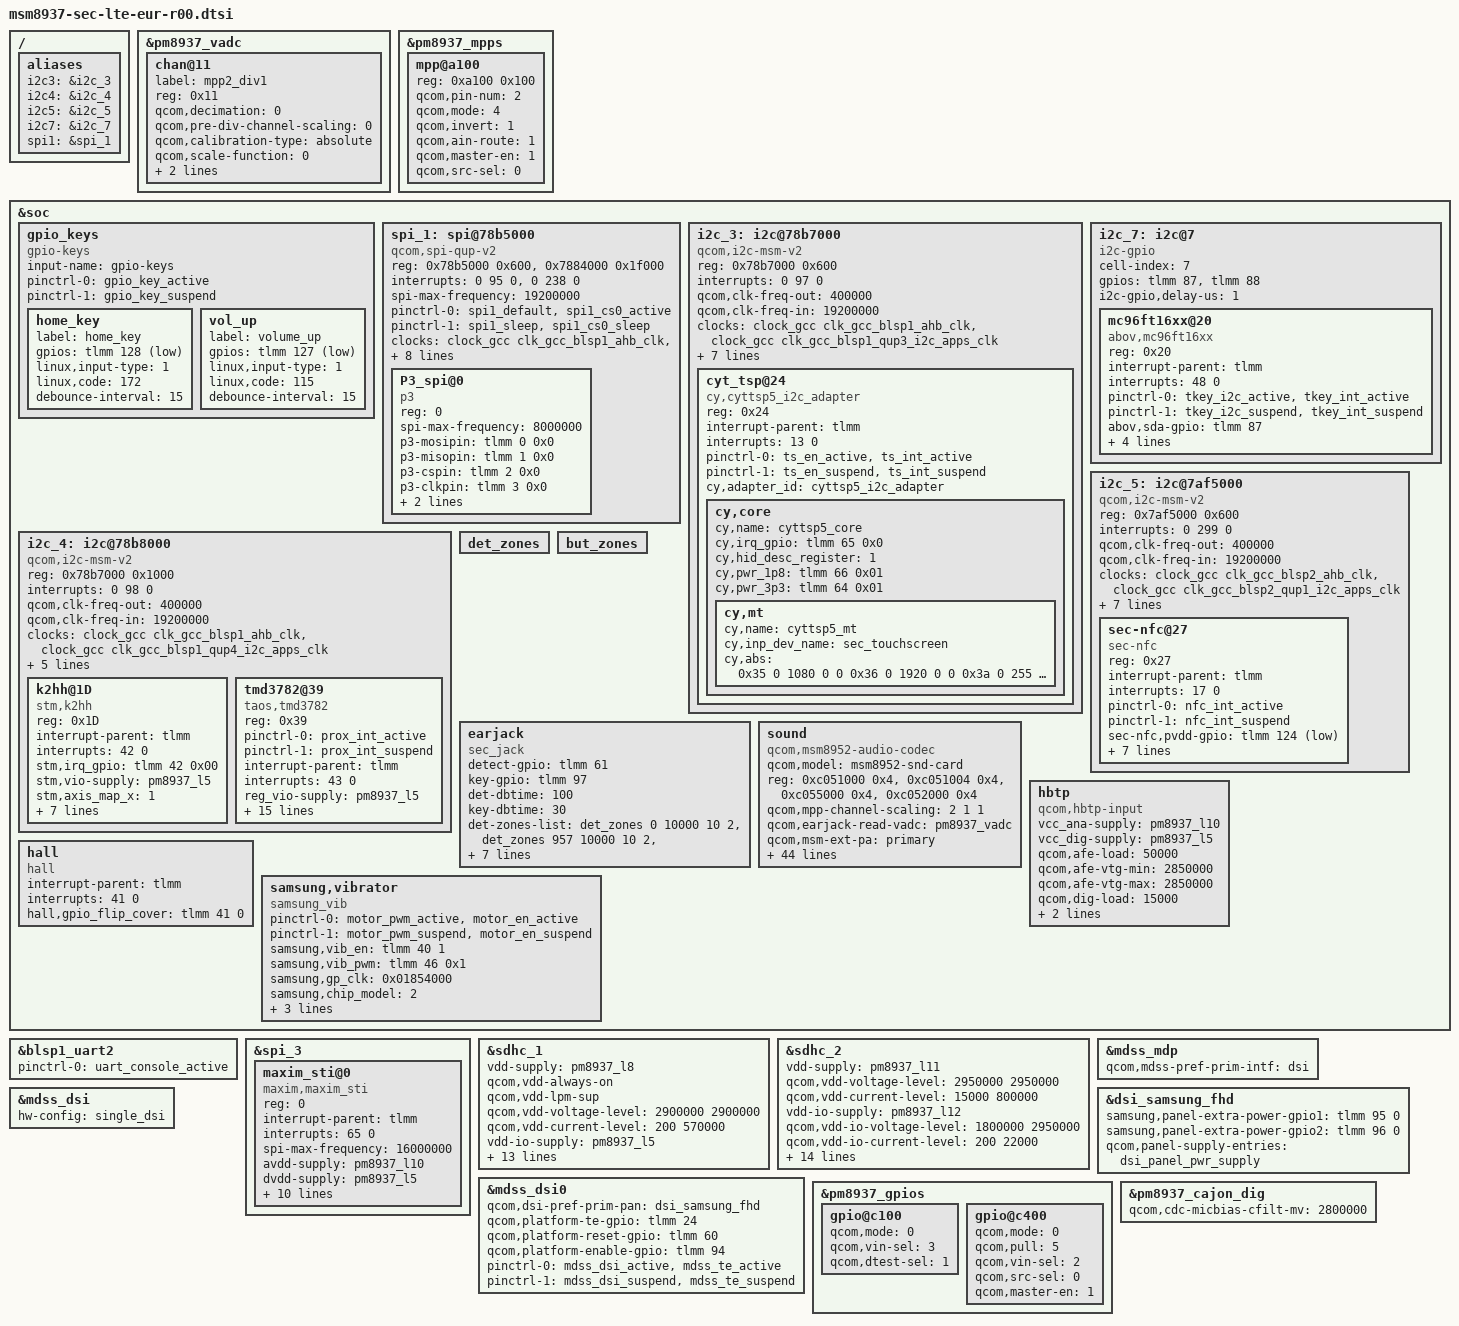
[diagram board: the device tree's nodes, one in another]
/*
 * Copyright (c) 2015, The Linux Foundation. All rights reserved.
 *
 * This program is free software; you can redistribute it and/or modify
 * it under the terms of the GNU General Public License version 2 and
 * only version 2 as published by the Free Software Foundation.
 *
 * This program is distributed in the hope that it will be useful,
 * but WITHOUT ANY WARRANTY; without even the implied warranty of
 * MERCHANTABILITY or FITNESS FOR A PARTICULAR PURPOSE.  See the
 * GNU General Public License for more details.
 */

#include "msm8937-sec-lte-common.dtsi"
#include "msm8937-pinctrl-sec-lte-eur-r00.dtsi"
#include "msm8937-camera-sensor-cdp.dtsi"

#include "msm8937-s2mu005.dtsi"
#include "msm8937-sec-lte-eur-battery-r00.dtsi"
#include <dt-bindings/clock/msm-clocks-8952.h>

/*
&flash_led {
	compatible = "qcom,qpnp-flash-led";
	reg = <0xd300 0x100>;
	pinctrl-names = "flash_led_enable","flash_led_disable";
	pinctrl-0 = <&rear_flash_led_enable>;
	pinctrl-1 = <&rear_flash_led_disable>;
	qcom,follow-otst2-rb-disabled;
};
*/
/{
	aliases {
		i2c3 = &i2c_3;
		i2c4 = &i2c_4;
		i2c5 = &i2c_5;
		i2c7 = &i2c_7;
		spi1 = &spi_1;
	};
};

&pm8937_vadc {
	chan@11 {
		label = "mpp2_div1";
		reg = <0x11>;
		qcom,decimation = <0>;
		qcom,pre-div-channel-scaling = <0>;
		qcom,calibration-type = "absolute";
		qcom,scale-function = <0>;
		qcom,hw-settle-time = <5>;
		qcom,fast-avg-setup = <0>;
	};
};

&pm8937_mpps {
	mpp@a100 {
		reg = <0xa100 0x100>;
		qcom,pin-num = <2>;
		qcom,mode = <4>; /* AIN input */
		qcom,invert = <1>; /* Enable MPP */
		qcom,ain-route = <1>; /* AMUX 6 */
		qcom,master-en = <1>;
		qcom,src-sel = <0>; /* Function constant */
		status = "okay";
	};
};
	
&soc {
	gpio_keys {
		compatible = "gpio-keys";
		input-name = "gpio-keys";
		pinctrl-names = "tlmm_gpio_key_active","tlmm_gpio_key_suspend";
		pinctrl-0 = <&gpio_key_active>;
		pinctrl-1 = <&gpio_key_suspend>;

		home_key {
			label = "home_key";
			gpios = <&tlmm 128 0x1>;
			linux,input-type = <1>;
			linux,code = <172>;
			debounce-interval = <15>;
		};

		vol_up {
			label = "volume_up";
			gpios = <&tlmm 127 0x1>;
			linux,input-type = <1>;
			linux,code = <115>;
			debounce-interval = <15>;
		};
	};
	
	/delete-node/ spi@0x78B5000;
	
	spi_1: spi@78b5000 { /* BLSP1 QUP0 */
		status = "ok";
		compatible = "qcom,spi-qup-v2";
		#address-cells = <1>;
		#size-cells = <0>;
		reg-names = "spi_physical", "spi_bam_physical";
		reg = <0x78b5000 0x600>,
			<0x7884000 0x1f000>;
		interrupt-names = "spi_irq", "spi_bam_irq";
		interrupts = <0 95 0>, <0 238 0>;
		spi-max-frequency = <19200000>;
		pinctrl-names = "spi_default", "spi_sleep";
		pinctrl-0 = <&spi1_default &spi1_cs0_active>;
		pinctrl-1 = <&spi1_sleep &spi1_cs0_sleep>;
		clocks = <&clock_gcc clk_gcc_blsp1_ahb_clk>,
			<&clock_gcc clk_gcc_blsp1_qup1_spi_apps_clk>;
		clock-names = "iface_clk", "core_clk";
		qcom,infinite-mode = <0>;
		qcom,use-bam;
		qcom,use-pinctrl;
		qcom,ver-reg-exists;
		qcom,bam-consumer-pipe-index = <4>;
		qcom,bam-producer-pipe-index = <5>;
		qcom,master-id = <86>;
		
		P3_spi@0 {
			compatible = "p3";
			reg = <0>;
			spi-max-frequency = <8000000>;
			p3-mosipin = <&tlmm 0 0x0>;
			p3-misopin = <&tlmm 1 0x0>;
			p3-cspin = <&tlmm 2 0x0>;
			p3-clkpin = <&tlmm 3 0x0>;
			p3-ese_pwr_req = <&tlmm 129 0>;
			p3-test = <0xBB>;
		};

	};

	i2c_3: i2c@78b7000 { /* BLSP1 QUP3 */
		compatible = "qcom,i2c-msm-v2";
		#address-cells = <1>;
		#size-cells = <0>;
		reg-names = "qup_phys_addr";
		reg = <0x78b7000 0x600>;
		interrupt-names = "qup_irq";
		interrupts = <0 97 0>;
		qcom,clk-freq-out = <400000>;
		qcom,clk-freq-in  = <19200000>;
		clock-names = "iface_clk", "core_clk";
		clocks = <&clock_gcc clk_gcc_blsp1_ahb_clk>,
			<&clock_gcc clk_gcc_blsp1_qup3_i2c_apps_clk>;

		pinctrl-names = "i2c_active", "i2c_sleep";
		pinctrl-0 = <&i2c_3_active>;
		pinctrl-1 = <&i2c_3_sleep>;
		qcom,noise-rjct-scl = <0>;
		qcom,noise-rjct-sda = <0>;
		qcom,master-id = <86>;
		dmas = <&dma_blsp1 8 64 0x20000020 0x20>,
			<&dma_blsp1 9 32 0x20000020 0x20>;
		dma-names = "tx", "rx";
		/*status = "disabled";*/
	
	};

	i2c@78b7000 { /* BLSP1 QUP2 */
                cyt_tsp@24 {
                        compatible = "cy,cyttsp5_i2c_adapter";
                        reg = <0x24>; /*slave address*/
                        interrupt-parent = <&tlmm>;
                        interrupts = <13 0>; /* Touch int gpio */
                        pinctrl-names = "tsp_i2c_gpio_active", "tsp_i2c_suspend";
                        pinctrl-0 = <&ts_en_active &ts_int_active>;
                        pinctrl-1 = <&ts_en_suspend &ts_int_suspend>;
                        cy,adapter_id = "cyttsp5_i2c_adapter";

				cy,core {
					cy,name = "cyttsp5_core";
					cy,irq_gpio = <&tlmm 65 0x0>;
					cy,hid_desc_register = <1>;
					cy,pwr_1p8 = <&tlmm 66 0x01>;
					cy,pwr_3p3 = <&tlmm 64 0x01>;  /* Touch En2 gpio */
					/*cy,ta_gpio = <&tlmm 98 0x01>; */
					cy,mt {
						cy,name = "cyttsp5_mt";
						cy,inp_dev_name = "sec_touchscreen";
						cy,abs =
							/* ABS_MT_POSITION_X, CY_ABS_MIN_X, CY_ABS_MAX_X, 0, 0 */
							<0x35 0 1080 0 0
							/* ABS_MT_POSITION_Y, CY_ABS_MIN_Y, CY_ABS_MAX_Y, 0, 0 */
							0x36 0 1920 0 0
							/* ABS_MT_PRESSURE, CY_ABS_MIN_P, CY_ABS_MAX_P, 0, 0 */
							0x3a 0 255 0 0
							/* CY_IGNORE_VALUE, CY_ABS_MIN_W, CY_ABS_MAX_W, 0, 0 */
							0xffff 0 255 0 0
							/* ABS_MT_TRACKING_ID, CY_ABS_MIN_T, CY_ABS_MAX_T, 0, 0 */
							0x39 0 15 0 0
							/* ABS_MT_TOUCH_MAJOR, 0, 255, 0, 0 */
							0x30 0 255 0 0
							/* ABS_MT_TOUCH_MINOR, 0, 255, 0, 0 */
							0x31 0 255 0 0
							/* ABS_MT_ORIENTATION, -128, 127, 0, 0 */
							0x34 0xfffffed7 127 0 0
							/* ABS_MT_TOOL_TYPE, 0, MT_TOOL_MAX, 0, 0 */
							0x37 0 1 0 0>;
					};
				};
                };
	};

	i2c_7: i2c@7 {
		cell-index = <7>;
		compatible = "i2c-gpio";
		gpios = <&tlmm 87 0 /* sda */
			&tlmm 88 0 /* scl */
			>;
		i2c-gpio,delay-us = <1>;
		#address-cells = <1>;
		#size-cells = <0>;
		mc96ft16xx@20{
			compatible = "abov,mc96ft16xx";
			reg = <0x20>;
			interrupt-parent = <&tlmm>;
			interrupts = <48 0>;
			pinctrl-names = "touchkey_active", "touchkey_suspend";
			pinctrl-0 = <&tkey_i2c_active &tkey_int_active>;
			pinctrl-1 = <&tkey_i2c_suspend &tkey_int_suspend>;
			abov,sda-gpio = <&tlmm 87 0>;
			abov,scl-gpio = <&tlmm 88 0>;
			abov,irq-gpio = <&tlmm 48 0>;
			abov,tkey_en-gpio = <&tlmm 92 0>;
			/*abov,tkey_led_en-gpio = <&tlmm 91 0>;*/
			vddo-supply = <&pm8937_l6>;
		};
	};

	i2c_4: i2c@78b8000 { /* BLSP1 QUP4 */
		compatible = "qcom,i2c-msm-v2";
		#address-cells = <1>;
		#size-cells = <0>;
		reg-names = "qup_phys_addr";
		reg = <0x78b7000 0x1000>;
		interrupt-names = "qup_irq";
		interrupts = <0 98 0>;
		qcom,clk-freq-out = <400000>;
		qcom,clk-freq-in  = <19200000>;
		clock-names = "iface_clk", "core_clk";
		clocks = <&clock_gcc clk_gcc_blsp1_ahb_clk>,
			<&clock_gcc clk_gcc_blsp1_qup4_i2c_apps_clk>;

		pinctrl-names = "i2c_active", "i2c_sleep";
		pinctrl-0 = <&i2c_4_active>;
		pinctrl-1 = <&i2c_4_sleep>;
		qcom,noise-rjct-scl = <0>;
		qcom,noise-rjct-sda = <0>;
		qcom,master-id = <86>;
		//dmas = <&dma_blsp1 8 64 0x20000020 0x20>,
		//	<&dma_blsp1 9 32 0x20000020 0x20>;
		//dma-names = "tx", "rx";
		/*status = "disabled";*/
	};
	i2c_4: i2c@78b8000 { /* BLSP1 QUP4 */
		k2hh@1D {
			compatible = "stm,k2hh";
			reg = <0x1D>;
			interrupt-parent = <&tlmm>;
			interrupts = <42 0>;
			stm,irq_gpio = <&tlmm 42 0x00>;
			stm,vio-supply = <&pm8937_l5>;
			stm,axis_map_x = <1>;
			stm,axis_map_y = <0>;
			stm,axis_map_z = <2>;
			stm,negate_x = <0>;
			stm,negate_y = <1>;
			stm,negate_z = <1>;
			stm,poll_interval = <100>;
			stm,min_interval = <2>;
		};
		tmd3782@39 {
			compatible = "taos,tmd3782";
			reg = <0x39>;
			pinctrl-names = "default";
			pinctrl-0 = <&prox_int_active>;
			pinctrl-1 = <&prox_int_suspend>;
			interrupt-parent = <&tlmm>;
			interrupts = <43 0>;
			reg_vio-supply = <&pm8937_l5>;
			reg_vdd-supply = <&pm8937_l17>;
			taos,irq_gpio = <&tlmm 43 0x1>;
			taos,prox_rawdata_trim = <170>;
			taos,prox_thresh_hi = <480>;
			taos,prox_thresh_low = <340>;
			taos,als_time = <0xEB>;
			taos,intr_filter = <0x33>;
			taos,prox_pulsecnt = <0x06>;
			taos,als_gain = <0x22>;
			taos,coef_atime = <50>;
			taos,ga = <97>;
			taos,coef_a = <1000>;
			taos,coef_b = <1880>;
			taos,coef_c = <642>;
			taos,coef_d = <1140>;
		};
	};

	i2c_5: i2c@7af5000 { /* BLSP2 QUP1 */
		compatible = "qcom,i2c-msm-v2";
		#address-cells = <1>;
		#size-cells = <0>;
		reg-names = "qup_phys_addr";
		reg = <0x7af5000 0x600>;
		interrupt-names = "qup_irq";
		interrupts = <0 299 0>;
		qcom,clk-freq-out = <400000>;
		qcom,clk-freq-in  = <19200000>;
		clock-names = "iface_clk", "core_clk";
		clocks = <&clock_gcc clk_gcc_blsp2_ahb_clk>,
			<&clock_gcc clk_gcc_blsp2_qup1_i2c_apps_clk>;

		pinctrl-names = "i2c_active", "i2c_sleep";
		pinctrl-0 = <&i2c_5_active>;
		pinctrl-1 = <&i2c_5_sleep>;
		qcom,noise-rjct-scl = <0>;
		qcom,noise-rjct-sda = <0>;
		qcom,master-id = <84>;
		dmas = <&dma_blsp2 4 64 0x20000020 0x20>,
			<&dma_blsp2 5 32 0x20000020 0x20>;
		dma-names = "tx", "rx";
	};
	i2c_5: i2c@7af5000 { 				
		sec-nfc@27 {
			compatible = "sec-nfc";
			reg = <0x27>;
			interrupt-parent = <&tlmm>;
			interrupts = <17 0>;
			pinctrl-names = "nfc_active","nfc_suspend";
			pinctrl-0 = <&nfc_int_active>;
			pinctrl-1 = <&nfc_int_suspend>;
			sec-nfc,pvdd-gpio = <&tlmm 124 0x01>;
			sec-nfc,firm-gpio = <&tlmm 13 0>;
			sec-nfc,ven-gpio = <&tlmm 16 0>;
			sec-nfc,irq-gpio = <&tlmm 17 0x00>;
			nfc_ldo-supply = <&pm8937_l14>;
			qcom,clk-src = "BBCLK2";
			qcom,clk-gpio = <&pm8937_gpios 5 0x00>;
			clocks = <&clock_gcc clk_bb_clk2_pin>;
			clock-names = "nfc_clock";
		};			
	};

	det_zones: det_zones {
		#list-det-cells = <4>;
	};

	but_zones: but_zones {
		#list-but-cells = <3>;
	};

	earjack {
		compatible = "sec_jack";
		detect-gpio = <&tlmm 61 0x0>;
		key-gpio = <&tlmm 97 0x0>;
		det-dbtime = <100>;
		key-dbtime = <30>;

		det-zones-list = <&det_zones 0 10000 10 2>,
				 <&det_zones 957 10000 10 2>,
				 <&det_zones 1057 10000 10 1>,
				 <&det_zones 9999 10000 10 1>;
		but-zones-list = <&but_zones 226 0 290>, /* KEY_MEDIA:226 */
				 <&but_zones 582 291 335>, /* KEY_VOICECOMMAND:582 */
				 <&but_zones 115 336 453>, /* KEY_VOLUMEUP:115 */
				 <&but_zones 114 454 700>; /* KEY_VOLUMEDOWN:114 */

		pinctrl-names = "earjack_gpio_active",
				"earjack_gpio_suspend";
		pinctrl-0 = <&earjack_det_act &earjack_switch_act>;
		pinctrl-1 = <&earjack_det_sus &earjack_switch_sus>;
	};

	sound {
		status = "okay";
		compatible = "qcom,msm8952-audio-codec";
		qcom,model = "msm8952-snd-card";
		reg = <0xc051000 0x4>,
		      <0xc051004 0x4>,
		      <0xc055000 0x4>,
		      <0xc052000 0x4>;
		reg-names = "csr_gp_io_mux_mic_ctl",
			    "csr_gp_io_mux_spkr_ctl",
			    "csr_gp_io_lpaif_pri_pcm_pri_mode_muxsel",
			    "csr_gp_io_mux_quin_ctl";

	 	qcom,mpp-channel-scaling = <2 1 1>;
		qcom,earjack-read-vadc = <&pm8937_vadc>;
		qcom,msm-ext-pa = "primary";
		qcom,msm-mclk-freq = <9600000>; 
		qcom,msm-hs-micbias-type = "internal";
		/delete-property/qcom,hdmi-dba-codec-rx;
		/delete-property/qcom,msm-mbhc-hphl-swh;
		/delete-property/qcom,msm-mbhc-gnd-swh;
		/delete-property/qcom,msm-micbias1-ext-cap;
		qcom,audio-routing =
			"RX_BIAS", "MCLK",
			"SPK_RX_BIAS", "MCLK",
			"INT_LDO_H", "MCLK",
			"MIC BIAS External", "Handset Mic",
			"MIC BIAS External2", "Headset Mic",
			"MIC BIAS External", "Secondary Mic",
			"AMIC1", "MIC BIAS External",
			"AMIC2", "MIC BIAS External2",
			"AMIC3", "MIC BIAS External";

		qcom,msm-gpios =
			"pri_i2s";
		qcom,pinctrl-names =
			"all_off",
			"pri_i2s_act";
		pinctrl-names =
			"all_off",
			"pri_i2s_act";
		pinctrl-0 = <&cdc_pdm_lines_sus &cdc_pdm_lines_2_sus>;
		pinctrl-1 = <&cdc_pdm_lines_act &cdc_pdm_lines_2_act>;

		asoc-platform = <&pcm0>, <&pcm1>, <&pcm2>, <&voip>, <&voice>,
				<&loopback>, <&compress>, <&hostless>,
				<&afe>, <&lsm>, <&routing>, <&lpa>;
		asoc-platform-names = "msm-pcm-dsp.0", "msm-pcm-dsp.1",
				"msm-pcm-dsp.2", "msm-voip-dsp",
				"msm-pcm-voice", "msm-pcm-loopback",
				"msm-compress-dsp", "msm-pcm-hostless",
				"msm-pcm-afe", "msm-lsm-client",
				"msm-pcm-routing", "msm-pcm-lpa";
		asoc-cpu = <&dai_pri_auxpcm>,
				<&dai_mi2s0>, <&dai_mi2s1>,
				<&dai_mi2s2>, <&dai_mi2s3>,
				<&dai_mi2s5>, <&dai_mi2s6>,
				<&bt_sco_rx>, <&bt_sco_tx>,
				<&int_fm_rx>, <&int_fm_tx>,
				<&afe_pcm_rx>, <&afe_pcm_tx>,
				<&afe_proxy_rx>, <&afe_proxy_tx>,
				<&incall_record_rx>, <&incall_record_tx>,
				<&incall_music_rx>, <&incall_music_2_rx>;
		asoc-cpu-names = "msm-dai-q6-auxpcm.1",
				"msm-dai-q6-mi2s.0", "msm-dai-q6-mi2s.1",
				"msm-dai-q6-mi2s.2", "msm-dai-q6-mi2s.3",
				"msm-dai-q6-mi2s.5", "msm-dai-q6-mi2s.6",
				"msm-dai-q6-dev.12288", "msm-dai-q6-dev.12289",
				"msm-dai-q6-dev.12292", "msm-dai-q6-dev.12293",
				"msm-dai-q6-dev.224", "msm-dai-q6-dev.225",
				"msm-dai-q6-dev.241", "msm-dai-q6-dev.240",
				"msm-dai-q6-dev.32771", "msm-dai-q6-dev.32772",
				"msm-dai-q6-dev.32773", "msm-dai-q6-dev.32770";

		asoc-codec = <&stub_codec>, <&pm8937_cajon_dig>;
		asoc-codec-names = "msm-stub-codec.1", "cajon_codec";
	};


	hbtp {
		compatible = "qcom,hbtp-input";
		vcc_ana-supply = <&pm8937_l10>;
		vcc_dig-supply = <&pm8937_l5>;
		qcom,afe-load = <50000>;
		qcom,afe-vtg-min = <2850000>;
		qcom,afe-vtg-max = <2850000>;
		qcom,dig-load = <15000>;
		qcom,dig-vtg-min = <1800000>;
		qcom,dig-vtg-max = <1800000>;
	};
	
	hall {
		status = "okay";
		compatible = "hall";
		interrupt-parent = <&tlmm>;
		interrupts = <41 0>;
		hall,gpio_flip_cover = <&tlmm 41 0>;
	};
	
	samsung,vibrator {
		compatible = "samsung_vib";
		pinctrl-names = "tlmm_motor_active","tlmm_motor_suspend";
		pinctrl-0 = <&motor_pwm_active &motor_en_active>;
		pinctrl-1 = <&motor_pwm_suspend &motor_en_suspend>;
		samsung,vib_en = <&tlmm 40 1>;
		samsung,vib_pwm = <&tlmm 46 0x1>;
		samsung,gp_clk = <0x01854000>;   // Address of GP0 clock
                samsung,chip_model = <2>;         // using ISA driver
                samsung,m_default = <3>;
                samsung,n_default = <137>;
                samsung,motor_strength = <96>;
		status = "ok";
	};

};

&blsp1_uart2 {
	status = "ok";
	pinctrl-names = "default";
	pinctrl-0 = <&uart_console_active>;
};
/*
&pmi_haptic{
	qcom,wave-play-rate-us = <4165>;
	qcom,actuator-type = "lra";
};
*/

&spi_3 { /* BLSP1 QUP3 */
	status = "ok";
	maxim_sti@0 {
		compatible = "maxim,maxim_sti";
		reg = <0>;
		interrupt-parent = <&tlmm>;
		interrupts = <65 0>;
		spi-max-frequency = <16000000>;
		avdd-supply = <&pm8937_l10>;
		dvdd-supply = <&pm8937_l5>;
		maxim_sti,irq-gpio = <&tlmm 65 0x00>;
		maxim_sti,reset-gpio = <&tlmm 64 0x00>;
		maxim_sti,touch_fusion = "/vendor/bin/touch_fusion";
		maxim_sti,config_file = "/etc/firmware/qtc800s.cfg";
		maxim_sti,fw_name = "qtc800s.bin";
		pinctrl-names = "pmx_ts_active","pmx_ts_suspend",
			"pmx_ts_release";
		pinctrl-0 = <&ts_int_active &ts_reset_active>;
		pinctrl-1 = <&ts_int_suspend &ts_reset_suspend>;
		pinctrl-2 = <&ts_release>;
	};
};

&sdhc_1 {
	/* device core power supply */
	vdd-supply = <&pm8937_l8>;
	qcom,vdd-always-on;
	qcom,vdd-lpm-sup;
	qcom,vdd-voltage-level = <2900000 2900000>;
	qcom,vdd-current-level = <200 570000>;

	/* device communication power supply */
	vdd-io-supply = <&pm8937_l5>;
	qcom,vdd-io-always-on;
	qcom,vdd-io-lpm-sup;
	qcom,vdd-io-voltage-level = <1800000 1800000>;
	qcom,vdd-io-current-level = <200 325000>;

	pinctrl-names = "active", "sleep";
	pinctrl-0 = <&sdc1_clk_on &sdc1_cmd_on &sdc1_data_on &sdc1_rclk_on>;
	pinctrl-1 = <&sdc1_clk_off &sdc1_cmd_off &sdc1_data_off &sdc1_rclk_off>;

	qcom,clk-rates = <400000 20000000 25000000 50000000 100000000 192000000
								384000000>;
	qcom,nonremovable;
	qcom,bus-speed-mode = "HS400_1p8v", "HS200_1p8v", "DDR_1p8v";

	status = "ok";
};

&sdhc_2 {
	/* device core power supply */
	vdd-supply = <&pm8937_l11>;
	qcom,vdd-voltage-level = <2950000 2950000>;
	qcom,vdd-current-level = <15000 800000>;

	/* device communication power supply */
	vdd-io-supply = <&pm8937_l12>;
	qcom,vdd-io-voltage-level = <1800000 2950000>;
	qcom,vdd-io-current-level = <200 22000>;

	pinctrl-names = "active", "sleep";
	pinctrl-0 = <&sdc2_clk_on &sdc2_cmd_on &sdc2_data_on &sdc2_cd_on>;
	pinctrl-1 = <&sdc2_clk_off &sdc2_cmd_off &sdc2_data_off>;

	#address-cells = <0>;
	interrupt-parent = <&sdhc_2>;
	interrupts = <0 1 2>;
	#interrupt-cells = <1>;
	interrupt-map-mask = <0xffffffff>;
	interrupt-map = <0 &intc 0 125 0
		1 &intc 0 221 0
		2 &tlmm 67 0>;
	interrupt-names = "hc_irq", "pwr_irq", "status_irq";
	cd-gpios = <&tlmm 67 0x1>;

	qcom,clk-rates = <400000 20000000 25000000 50000000 100000000
								200000000>;
	qcom,bus-speed-mode = "SDR12", "SDR25", "SDR50", "DDR50", "SDR104";

	status = "ok";
};

#include "../samsung/msm8937/msm8937-mdss-panels.dtsi"
#include "../../../../../../drivers/video/msm/mdss/samsung/S6E3FA2_AMS549EH01/dsi_panel_S6E3FA2_AMS549EH01_fhd_octa_cmd.dtsi"

&mdss_mdp {
	qcom,mdss-pref-prim-intf = "dsi";
};

&mdss_dsi {
	hw-config = "single_dsi";
};

&dsi_samsung_fhd {
	samsung,panel-extra-power-gpio1 = <&tlmm 95 0>;
	samsung,panel-extra-power-gpio2 = <&tlmm 96 0>;
	qcom,panel-supply-entries = <&dsi_panel_pwr_supply>;
};

&mdss_dsi0 {
	qcom,dsi-pref-prim-pan = <&dsi_samsung_fhd>;

	qcom,platform-te-gpio = <&tlmm 24 0>;
	qcom,platform-reset-gpio = <&tlmm 60 0>;
	qcom,platform-enable-gpio = <&tlmm 94 0>;

	pinctrl-names = "mdss_default", "mdss_sleep";
	pinctrl-0 = <&mdss_dsi_active &mdss_te_active>;
	pinctrl-1 = <&mdss_dsi_suspend &mdss_te_suspend>;
};

/* PM8937 GPIO configuration */
&pm8937_gpios {
	gpio@c100 {
		qcom,mode = <0>;
		qcom,vin-sel = <3>;
		qcom,dtest-sel = <1>;
		status = "okay";
	};
	
	gpio@c400 { /* GPIO 5 */
		/* NFC_CLK_REQ */
		qcom,mode = <0>; /* QPNP_PIN_MODE_DIG_IN */
		qcom,pull = <5>; /* QPNP_PIN_PULL_NONE */
		qcom,vin-sel = <2>; /* QPNP_PIN_VIN2 */
		qcom,src-sel = <0>; /* QPNP_PIN_SEL_FUNC_0 */
		qcom,master-en = <1>;
		status = "okay";
	};
};

&pm8937_cajon_dig {
	qcom,cdc-micbias-cfilt-mv = <2800000>;
};
